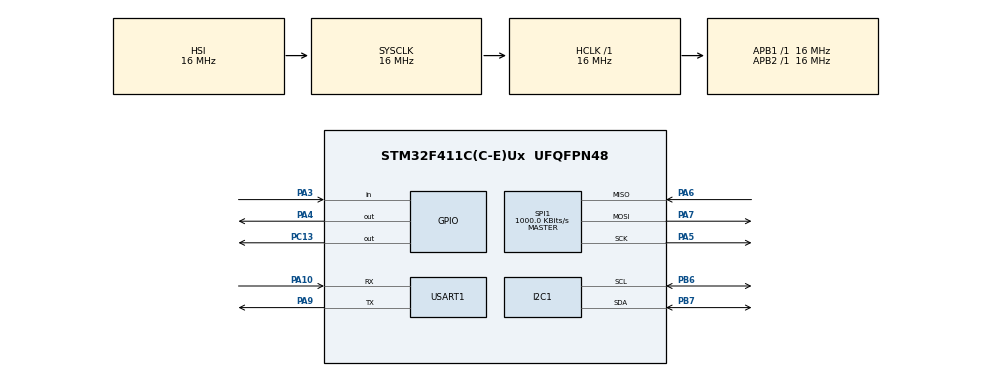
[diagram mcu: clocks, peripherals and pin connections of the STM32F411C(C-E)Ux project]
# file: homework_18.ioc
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Mcu.Family=STM32F4
Mcu.Name=STM32F411C(C-E)Ux
Mcu.Package=UFQFPN48
NVIC.I2C1_ER_IRQn=true\:0\:0\:false\:false\:true\:true\:true\:true
NVIC.I2C1_EV_IRQn=true\:0\:0\:false\:false\:true\:true\:true\:true
NVIC.PriorityGroup=NVIC_PRIORITYGROUP_4
NVIC.SPI1_IRQn=true\:0\:0\:false\:false\:true\:true\:true\:true
NVIC.TIM1_BRK_TIM9_IRQn=true\:0\:0\:false\:false\:true\:true\:true\:true
NVIC.TIM1_CC_IRQn=true\:0\:0\:false\:false\:true\:true\:true\:true
NVIC.TIM1_TRG_COM_TIM11_IRQn=true\:0\:0\:false\:false\:true\:true\:true\:true
NVIC.TIM1_UP_TIM10_IRQn=true\:0\:0\:false\:false\:true\:true\:true\:true
PA10.Mode=Asynchronous
PA10.Signal=USART1_RX
PA13.Mode=Serial_Wire
PA13.Signal=SYS_JTMS-SWDIO
PA14.Mode=Serial_Wire
PA14.Signal=SYS_JTCK-SWCLK
PA3.GPIO_PuPd=GPIO_NOPULL
PA3.Signal=GPIO_Input
PA4.GPIO_ModeDefaultOutputPP=GPIO_MODE_OUTPUT_PP
PA4.GPIO_PuPd=GPIO_NOPULL
PA4.GPIO_Speed=GPIO_SPEED_FREQ_HIGH
PA4.PinState=GPIO_PIN_SET
PA4.Signal=GPIO_Output
PA5.Mode=Full_Duplex_Master
PA5.Signal=SPI1_SCK
PA6.Mode=Full_Duplex_Master
PA6.Signal=SPI1_MISO
PA7.Mode=Full_Duplex_Master
PA7.Signal=SPI1_MOSI
PA9.Mode=Asynchronous
PA9.Signal=USART1_TX
PB6.Mode=I2C
PB6.Signal=I2C1_SCL
PB7.Mode=I2C
PB7.Signal=I2C1_SDA
PC13-ANTI_TAMP.Signal=GPIO_Output
PH0\ -\ OSC_IN.Mode=HSE-External-Oscillator
PH0\ -\ OSC_IN.Signal=RCC_OSC_IN
PH1\ -\ OSC_OUT.Mode=HSE-External-Oscillator
PH1\ -\ OSC_OUT.Signal=RCC_OSC_OUT
ProjectManager.HeapSize=0x200
ProjectManager.StackSize=0x400
ProjectManager.TargetToolchain=CMake
RCC.AHBFreq_Value=16000000
RCC.APB1Freq_Value=16000000
RCC.APB2Freq_Value=16000000
RCC.CortexFreq_Value=16000000
RCC.HSE_VALUE=25000000
RCC.HSI_VALUE=16000000
RCC.LSE_VALUE=32768
RCC.SYSCLKFreq_VALUE=16000000
RCC.VCOOutputFreq_Value=192000000
SPI1.BaudRatePrescaler=SPI_BAUDRATEPRESCALER_16
SPI1.CLKPhase=SPI_PHASE_1EDGE
SPI1.CalculateBaudRate=1000.0 KBits/s
SPI1.Direction=SPI_DIRECTION_2LINES
SPI1.Mode=SPI_MODE_MASTER
SPI1.VirtualType=VM_MASTER
TIM1.Period=16000
TIM1.Prescaler=500
USART1.VirtualMode=VM_ASYNC
VP_TIM1_VS_ClockSourceINT.Mode=Internal
board=custom

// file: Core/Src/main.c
/* USER CODE BEGIN Header */
/**
  ******************************************************************************
  * @file           : main.c
  * @brief          : Main program body
  ******************************************************************************
  * @attention
  *
  * Copyright (c) 2026 STMicroelectronics.
  * All rights reserved.
  *
  * This software is licensed under terms that can be found in the LICENSE file
  * in the root directory of this software component.
  * If no LICENSE file comes with this software, it is provided AS-IS.
  *
  ******************************************************************************
  */
/* USER CODE END Header */
#include "main.h"

/* USER CODE BEGIN Includes */
#include "app.h"
/* USER CODE END Includes */

I2C_HandleTypeDef hi2c1;

SPI_HandleTypeDef hspi1;

TIM_HandleTypeDef htim1;

UART_HandleTypeDef huart1;

void SystemClock_Config(void);
static void MX_GPIO_Init(void);
static void MX_USART1_UART_Init(void);
static void MX_TIM1_Init(void);
static void MX_I2C1_Init(void);
static void MX_SPI1_Init(void);

int main(void)
{

  /* MCU Configuration--------------------------------------------------------*/

  /* Reset of all peripherals, Initializes the Flash interface and the Systick. */
  HAL_Init();

  /* Configure the system clock */
  SystemClock_Config();

  /* Initialize all configured peripherals */
  MX_GPIO_Init();
  MX_USART1_UART_Init();
  MX_TIM1_Init();
  MX_I2C1_Init();
  MX_SPI1_Init();

  /* Infinite loop */
  /* USER CODE BEGIN WHILE */
  // while (1)
  // {
    app_start();
    /* USER CODE END WHILE */

    /* USER CODE BEGIN 3 */
  // }
  /* USER CODE END 3 */
}

void SystemClock_Config(void)
{
  RCC_OscInitTypeDef RCC_OscInitStruct = {0};
  RCC_ClkInitTypeDef RCC_ClkInitStruct = {0};

  /** Configure the main internal regulator output voltage
  */
  __HAL_RCC_PWR_CLK_ENABLE();
  __HAL_PWR_VOLTAGESCALING_CONFIG(PWR_REGULATOR_VOLTAGE_SCALE1);

  /** Initializes the RCC Oscillators according to the specified parameters
  * in the RCC_OscInitTypeDef structure.
  */
  RCC_OscInitStruct.OscillatorType = RCC_OSCILLATORTYPE_HSI;
  RCC_OscInitStruct.HSIState = RCC_HSI_ON;
  RCC_OscInitStruct.HSICalibrationValue = RCC_HSICALIBRATION_DEFAULT;
  RCC_OscInitStruct.PLL.PLLState = RCC_PLL_NONE;
  if (HAL_RCC_OscConfig(&RCC_OscInitStruct) != HAL_OK)
  {
    Error_Handler();
  }

  /** Initializes the CPU, AHB and APB buses clocks
  */
  RCC_ClkInitStruct.ClockType = RCC_CLOCKTYPE_HCLK|RCC_CLOCKTYPE_SYSCLK
                              |RCC_CLOCKTYPE_PCLK1|RCC_CLOCKTYPE_PCLK2;
  RCC_ClkInitStruct.SYSCLKSource = RCC_SYSCLKSOURCE_HSI;
  RCC_ClkInitStruct.AHBCLKDivider = RCC_SYSCLK_DIV1;
  RCC_ClkInitStruct.APB1CLKDivider = RCC_HCLK_DIV1;
  RCC_ClkInitStruct.APB2CLKDivider = RCC_HCLK_DIV1;

  if (HAL_RCC_ClockConfig(&RCC_ClkInitStruct, FLASH_LATENCY_0) != HAL_OK)
  {
    Error_Handler();
  }
}

static void MX_I2C1_Init(void)
{

  hi2c1.Instance = I2C1;
  hi2c1.Init.ClockSpeed = 100000;
  hi2c1.Init.DutyCycle = I2C_DUTYCYCLE_2;
  hi2c1.Init.OwnAddress1 = 0;
  hi2c1.Init.AddressingMode = I2C_ADDRESSINGMODE_7BIT;
  hi2c1.Init.DualAddressMode = I2C_DUALADDRESS_DISABLE;
  hi2c1.Init.OwnAddress2 = 0;
  hi2c1.Init.GeneralCallMode = I2C_GENERALCALL_DISABLE;
  hi2c1.Init.NoStretchMode = I2C_NOSTRETCH_DISABLE;
  if (HAL_I2C_Init(&hi2c1) != HAL_OK)
  {
    Error_Handler();
  }

}

static void MX_SPI1_Init(void)
{

  /* SPI1 parameter configuration*/
  hspi1.Instance = SPI1;
  hspi1.Init.Mode = SPI_MODE_MASTER;
  hspi1.Init.Direction = SPI_DIRECTION_2LINES;
  hspi1.Init.DataSize = SPI_DATASIZE_8BIT;
  hspi1.Init.CLKPolarity = SPI_POLARITY_LOW;
  hspi1.Init.CLKPhase = SPI_PHASE_1EDGE;
  hspi1.Init.NSS = SPI_NSS_SOFT;
  hspi1.Init.BaudRatePrescaler = SPI_BAUDRATEPRESCALER_16;
  hspi1.Init.FirstBit = SPI_FIRSTBIT_MSB;
  hspi1.Init.TIMode = SPI_TIMODE_DISABLE;
  hspi1.Init.CRCCalculation = SPI_CRCCALCULATION_DISABLE;
  hspi1.Init.CRCPolynomial = 10;
  if (HAL_SPI_Init(&hspi1) != HAL_OK)
  {
    Error_Handler();
  }

}

static void MX_TIM1_Init(void)
{

  TIM_ClockConfigTypeDef sClockSourceConfig = {0};
  TIM_MasterConfigTypeDef sMasterConfig = {0};

  htim1.Instance = TIM1;
  htim1.Init.Prescaler = 500;
  htim1.Init.CounterMode = TIM_COUNTERMODE_UP;
  htim1.Init.Period = 16000;
  htim1.Init.ClockDivision = TIM_CLOCKDIVISION_DIV1;
  htim1.Init.RepetitionCounter = 0;
  htim1.Init.AutoReloadPreload = TIM_AUTORELOAD_PRELOAD_DISABLE;
  if (HAL_TIM_Base_Init(&htim1) != HAL_OK)
  {
    Error_Handler();
  }
  sClockSourceConfig.ClockSource = TIM_CLOCKSOURCE_INTERNAL;
  if (HAL_TIM_ConfigClockSource(&htim1, &sClockSourceConfig) != HAL_OK)
  {
    Error_Handler();
  }
  sMasterConfig.MasterOutputTrigger = TIM_TRGO_RESET;
  sMasterConfig.MasterSlaveMode = TIM_MASTERSLAVEMODE_DISABLE;
  if (HAL_TIMEx_MasterConfigSynchronization(&htim1, &sMasterConfig) != HAL_OK)
  {
    Error_Handler();
  }

}

static void MX_USART1_UART_Init(void)
{

  huart1.Instance = USART1;
  huart1.Init.BaudRate = 115200;
  huart1.Init.WordLength = UART_WORDLENGTH_8B;
  huart1.Init.StopBits = UART_STOPBITS_1;
  huart1.Init.Parity = UART_PARITY_NONE;
  huart1.Init.Mode = UART_MODE_TX_RX;
  huart1.Init.HwFlowCtl = UART_HWCONTROL_NONE;
  huart1.Init.OverSampling = UART_OVERSAMPLING_16;
  if (HAL_UART_Init(&huart1) != HAL_OK)
  {
    Error_Handler();
  }

}

static void MX_GPIO_Init(void)
{
  GPIO_InitTypeDef GPIO_InitStruct = {0};

  /* GPIO Ports Clock Enable */
  __HAL_RCC_GPIOC_CLK_ENABLE();
  __HAL_RCC_GPIOH_CLK_ENABLE();
  __HAL_RCC_GPIOA_CLK_ENABLE();
  __HAL_RCC_GPIOB_CLK_ENABLE();

  /*Configure GPIO pin Output Level */
  HAL_GPIO_WritePin(GPIOC, GPIO_PIN_13, GPIO_PIN_RESET);

  /*Configure GPIO pin Output Level */
  HAL_GPIO_WritePin(GPIOA, GPIO_PIN_4, GPIO_PIN_SET);

  /*Configure GPIO pin : PC13 */
  GPIO_InitStruct.Pin = GPIO_PIN_13;
  GPIO_InitStruct.Mode = GPIO_MODE_OUTPUT_PP;
  GPIO_InitStruct.Pull = GPIO_NOPULL;
  GPIO_InitStruct.Speed = GPIO_SPEED_FREQ_LOW;
  HAL_GPIO_Init(GPIOC, &GPIO_InitStruct);

  /*Configure GPIO pin : PA3 */
  GPIO_InitStruct.Pin = GPIO_PIN_3;
  GPIO_InitStruct.Mode = GPIO_MODE_INPUT;
  GPIO_InitStruct.Pull = GPIO_NOPULL;
  HAL_GPIO_Init(GPIOA, &GPIO_InitStruct);

  /*Configure GPIO pin : PA4 */
  GPIO_InitStruct.Pin = GPIO_PIN_4;
  GPIO_InitStruct.Mode = GPIO_MODE_OUTPUT_PP;
  GPIO_InitStruct.Pull = GPIO_NOPULL;
  GPIO_InitStruct.Speed = GPIO_SPEED_FREQ_HIGH;
  HAL_GPIO_Init(GPIOA, &GPIO_InitStruct);

}

void Error_Handler(void)
{
  __disable_irq();
  while (1)
  {
  }
}
